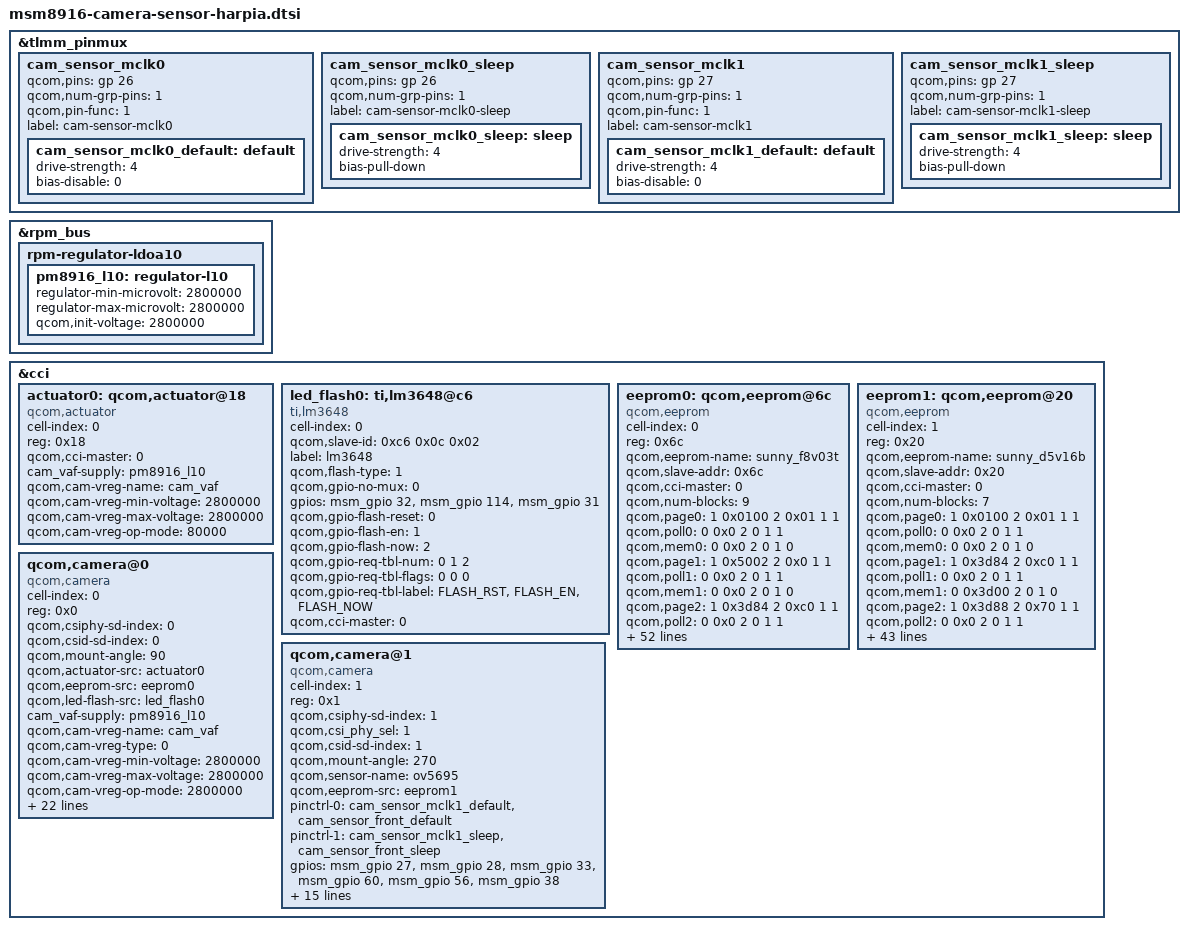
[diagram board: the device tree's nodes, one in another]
/*
 * Copyright (c) 2016, The Linux Foundation. All rights reserved.
 *
 * This program is free software; you can redistribute it and/or modify
 * it under the terms of the GNU General Public License version 2 and
 * only version 2 as published by the Free Software Foundation.
 *
 * This program is distributed in the hope that it will be useful,
 * but WITHOUT ANY WARRANTY; without even the implied warranty of
 * MERCHANTABILITY or FITNESS FOR A PARTICULAR PURPOSE.  See the
 * GNU General Public License for more details.
 */

&tlmm_pinmux {
	cam_sensor_mclk0 {
		/* MCLK */
		qcom,pins = <&gp 26>;
		qcom,num-grp-pins = <1>;
		qcom,pin-func = <1>;
		label = "cam-sensor-mclk0";
		/* active state */
		cam_sensor_mclk0_default: default {
			drive-strength = <4>; /* 4 MA */
			bias-disable = <0>; /* No PULL */
		};
	};

	cam_sensor_mclk0_sleep {
		/* MCLK */
		qcom,pins = <&gp 26>;
		qcom,num-grp-pins = <1>;
		label = "cam-sensor-mclk0-sleep";
		/* suspend state */
		cam_sensor_mclk0_sleep: sleep {
			drive-strength = <4>; /* 4 MA */
			bias-pull-down; /* PULL DOWN */
		};
	};

	cam_sensor_mclk1 {
		/* MCLK */
		qcom,pins = <&gp 27>;
		qcom,num-grp-pins = <1>;
		qcom,pin-func = <1>;
		label = "cam-sensor-mclk1";
		/* active state */
		cam_sensor_mclk1_default: default {
			drive-strength = <4>; /* 4 MA */
			bias-disable = <0>; /* No PULL */
		};
	};

	cam_sensor_mclk1_sleep {
		/* MCLK */
		qcom,pins = <&gp 27>;
		qcom,num-grp-pins = <1>;
		label = "cam-sensor-mclk1-sleep";
		/* suspend state */
		cam_sensor_mclk1_sleep: sleep {
			drive-strength = <4>; /* 4 MA */
			bias-pull-down; /* PULL DOWN */
		};
	};
};

&rpm_bus {
	rpm-regulator-ldoa10 {
		status = "okay";
		pm8916_l10: regulator-l10 {
			status = "okay";
			regulator-min-microvolt = <2800000>;
			regulator-max-microvolt = <2800000>;
			qcom,init-voltage = <2800000>;
		};
	};
};

&cci {

	actuator0: qcom,actuator@18 {
		cell-index = <0>;
		reg = <0x18>;
		compatible = "qcom,actuator";
		qcom,cci-master = <0>;
		cam_vaf-supply = <&pm8916_l10>;
		qcom,cam-vreg-name = "cam_vaf";
		qcom,cam-vreg-min-voltage = <2800000>;
		qcom,cam-vreg-max-voltage = <2800000>;
		qcom,cam-vreg-op-mode = <80000>;
	};

	/* LM3648 flash LED driver*/
	led_flash0: ti,lm3648@c6 {
		cell-index = <0>;
		qcom,slave-id = <0xc6 0x0c 0x02>;
		compatible = "ti,lm3648";
		label = "lm3648";
		qcom,flash-type = <1>;
		qcom,gpio-no-mux = <0>;
		gpios = <&msm_gpio 32 0>, /*FLASH_RST(HW_EN)*/
			<&msm_gpio 114 0>, /*TORCH_EN*/
			<&msm_gpio 31 0>; /*FLASH_NOW*/
		qcom,gpio-flash-reset = <0>;
		qcom,gpio-flash-en = <1>;
		qcom,gpio-flash-now = <2>;
		qcom,gpio-req-tbl-num = <0 1 2>;
		qcom,gpio-req-tbl-flags = <0 0 0>;
		qcom,gpio-req-tbl-label = "FLASH_RST",
			"FLASH_EN",
			"FLASH_NOW";
		qcom,cci-master = <0>;
	};

	eeprom0: qcom,eeprom@6c{
		cell-index = <0>;
		reg = <0x6c>;
		qcom,eeprom-name = "sunny_f8v03t";
		compatible = "qcom,eeprom";
		qcom,slave-addr = <0x6c>;
		qcom,cci-master = <0>;
		qcom,num-blocks = <9>;

		qcom,page0 = <1 0x0100 2 0x01 1 1>;
		qcom,poll0 = <0 0x0 2 0 1 1>;
		qcom,mem0 = <0 0x0 2 0 1 0>;

		qcom,page1 = <1 0x5002 2 0x0 1 1>;
		qcom,poll1 = <0 0x0 2 0 1 1>;
		qcom,mem1 = <0 0x0 2 0 1 0>;

		qcom,page2 = <1 0x3d84 2 0xc0 1 1>;
		qcom,poll2 = <0 0x0 2 0 1 1>;
		qcom,mem2 = <0 0x3d00 2 0 1 0>;

		qcom,page3 = <1 0x3d88 2 0x70 1 1>;
		qcom,poll3 = <0 0x0 2 0 1 1>;
		qcom,mem3 = <0 0x3d00 2 0 1 0>;

		qcom,page4 = <1 0x3d89 2 0x10 1 1>;
		qcom,poll4 = <0 0x0 2 0 1 1>;
		qcom,mem4 = <0 0x3d00 2 0 1 0>;

		qcom,page5 = <1 0x3d8A 2 0x71 1 1>;
		qcom,poll5 = <0 0x0 2 0 1 1>;
		qcom,mem5 = <0 0x3d00 2 0 1 0>;

		qcom,page6 = <1 0x3d8B 2 0x15 1 1>;
		qcom,poll6 = <0 0x0 2 0 1 1>;
		qcom,mem6 = <0 0x3d00 2 0 1 0>;

		qcom,page7 = <1 0x3d81 2 0x01 1 10>;
		qcom,poll7 = <0 0x0 2 0 1 1>;
		qcom,mem7 = <278 0x7000 2 0 1 1>;

		qcom,page8 = <1 0x5002 2 0x08 1 1>;
		qcom,poll8 = <0 0x0 2 0 1 1>;
		qcom,mem8 = <0 0x0 2 0 1 0>;

		pinctrl-names = "cam_default", "cam_suspend";
		pinctrl-0 = <&cam_sensor_mclk0_default &cam_sensor_rear_default>;
		pinctrl-1 = <&cam_sensor_mclk0_sleep &cam_sensor_rear_sleep>;
		qcom,gpio-no-mux = <0>;
		gpios = <&msm_gpio 26 0>,
			<&msm_gpio 35 0>,
			<&msm_gpio 34 0>,
			<&msm_gpio 60 0>,
			<&msm_gpio 56 0>,
			<&msm_gpio 38 0>;
		qcom,gpio-reset = <1>;
		qcom,gpio-standby = <2>;
		qcom,gpio-vio = <3>;
		qcom,gpio-vdig = <4>;
		qcom,gpio-vana= <5>;
		qcom,gpio-req-tbl-num = <0 1 2 3 4 5>;
		qcom,gpio-req-tbl-flags = <1 0 0 0 0 0>;
		qcom,gpio-req-tbl-label = "CAMIF_MCLK",
			"CAM_RESET1",
			"CAM_STANDBY",
			"CAM_VIO",
			"CAM_VDIG",
			"CAM_VANA";
		qcom,gpio-set-tbl-num = <1 1>;
		qcom,gpio-set-tbl-flags = <0 2>;
		qcom,gpio-set-tbl-delay = <1000 4000>;
		qcom,csi-lane-assign = <0x4320>;
		qcom,csi-lane-mask = <0x3>;
		qcom,cam-power-seq-type = "sensor_gpio", "sensor_gpio", "sensor_gpio",
			"sensor_gpio", "sensor_gpio" , "sensor_clk";
		qcom,cam-power-seq-val = "sensor_gpio_vana", "sensor_gpio_vio", "sensor_gpio_vdig",
			"sensor_gpio_reset", "sensor_gpio_standby","sensor_cam_mclk";
		qcom,cam-power-seq-cfg-val = <1 1 1 1 1 23880000>;
		qcom,cam-power-seq-delay = <1 2 1 10 10 10>;
		clocks = <&clock_gcc clk_mclk0_clk_src>,
				<&clock_gcc clk_gcc_camss_mclk0_clk>;
		clock-names = "cam_src_clk", "cam_clk";
	};

	eeprom1: qcom,eeprom@20 {
		cell-index = <1>;
		reg = <0x20>;
		qcom,eeprom-name = "sunny_d5v16b";
		compatible = "qcom,eeprom";
		qcom,slave-addr = <0x20>;
		qcom,cci-master = <0>;
		qcom,num-blocks = <7>;

		qcom,page0 = <1 0x0100 2 0x01 1 1>;
		qcom,poll0 = <0 0x0 2 0 1 1>;
		qcom,mem0 = <0 0x0 2 0 1 0>;

		qcom,page1 = <1 0x3d84 2 0xc0 1 1>;
		qcom,poll1 = <0 0x0 2 0 1 1>;
		qcom,mem1 = <0 0x3d00 2 0 1 0>;

		qcom,page2 = <1 0x3d88 2 0x70 1 1>;
		qcom,poll2 = <0 0x0 2 0 1 1>;
		qcom,mem2 = <0 0x3d00 2 0 1 0>;

		qcom,page3 = <1 0x3d89 2 0x0C 1 1>;
		qcom,poll3 = <0 0x0 2 0 1 1>;
		qcom,mem3 = <0 0x3d00 2 0 1 0>;

		qcom,page4 = <1 0x3d8A 2 0x70 1 1>;
		qcom,poll4 = <0 0x0 2 0 1 1>;
		qcom,mem4 = <0 0x3d00 2 0 1 0>;

		qcom,page5 = <1 0x3d8B 2 0x1B 1 1>;
		qcom,poll5 = <0 0x0 2 0 1 1>;
		qcom,mem5 = <0 0x3d00 2 0 1 0>;

		qcom,page6 = <1 0x3d81 2 0x01 1 10>;
		qcom,poll6 = <0 0x0 2 0 1 1>;
		qcom,mem6 = <28 0x7000 2 0 1 1>;

		pinctrl-names = "cam_default", "cam_suspend";
		pinctrl-0 = <&cam_sensor_mclk1_default &cam_sensor_front_default>;
		pinctrl-1 = <&cam_sensor_mclk1_sleep &cam_sensor_front_sleep>;
		gpios = <&msm_gpio 27 0>,
			<&msm_gpio 28 0>,
			<&msm_gpio 33 0>,
			<&msm_gpio 60 0>,
			<&msm_gpio 56 0>,
			<&msm_gpio 38 0>;
		qcom,gpio-reset = <1>;
		qcom,gpio-standby = <2>;
		qcom,gpio-vio = <3>;
		qcom,gpio-vdig = <4>;
		qcom,gpio-vana = <5>;
		qcom,gpio-req-tbl-num = <0 1 2 3 4 5>;
		qcom,gpio-req-tbl-flags = <1 0 0 0 0 0>;
		qcom,gpio-req-tbl-label = "CAMIF_MCLK",
			"CAM_RESET",
			"CAM_STANDBY",
			"CAM_VIO",
			"CAM_VDIG",
			"CAM_VANA";
		qcom,gpio-set-tbl-num = <1 1>;
		qcom,gpio-set-tbl-flags = <0 2>;
		qcom,gpio-set-tbl-delay = <1000 4000>;
		qcom,cam-power-seq-type = "sensor_gpio", "sensor_gpio", "sensor_gpio",
			"sensor_gpio", "sensor_gpio" , "sensor_clk";
		qcom,cam-power-seq-val = "sensor_gpio_vana", "sensor_gpio_vio", "sensor_gpio_vdig",
			"sensor_gpio_standby", "sensor_gpio_reset", "sensor_cam_mclk";
		qcom,cam-power-seq-cfg-val = <1 1 1 1 1 23880000>;
		qcom,cam-power-seq-delay = <1 2 1 10 10 10>;
		clocks = <&clock_gcc clk_mclk1_clk_src>,
				<&clock_gcc clk_gcc_camss_mclk1_clk>;
		clock-names = "cam_src_clk", "cam_clk";
	};

	qcom,camera@0 {
		cell-index = <0>;
		compatible = "qcom,camera";
		reg = <0x0>;
		qcom,csiphy-sd-index = <0>;
		qcom,csid-sd-index = <0>;
		qcom,mount-angle = <90>;
		qcom,actuator-src = <&actuator0>;
		qcom,eeprom-src = <&eeprom0>;
		qcom,led-flash-src = <&led_flash0>;
		cam_vaf-supply = <&pm8916_l10>;
		qcom,cam-vreg-name = "cam_vaf";
		qcom,cam-vreg-type = <0>;
		qcom,cam-vreg-min-voltage = <2800000>;
		qcom,cam-vreg-max-voltage = <2800000>;
		qcom,cam-vreg-op-mode = <2800000>;
		pinctrl-names = "cam_default", "cam_suspend";
		pinctrl-0 = <&cam_sensor_mclk0_default &cam_sensor_rear_default>;
		pinctrl-1 = <&cam_sensor_mclk0_sleep &cam_sensor_rear_sleep>;
		gpios = <&msm_gpio 26 0>,
			<&msm_gpio 35 0>,
			<&msm_gpio 34 0>,
			<&msm_gpio 60 0>,
			<&msm_gpio 56 0>,
			<&msm_gpio 38 0>;
		qcom,gpio-reset = <1>;
		qcom,gpio-standby = <2>;
		qcom,gpio-vio = <3>;
		qcom,gpio-vdig = <4>;
		qcom,gpio-vana= <5>;
		qcom,gpio-req-tbl-num = <0 1 2 3 4 5>;
		qcom,gpio-req-tbl-flags = <1 0 0 0 0 0>;
		qcom,gpio-req-tbl-label = "CAMIF_MCLK",
			"CAM_RESET1",
			"CAM_STANDBY",
			"CAM_VIO",
			"CAM_VDIG",
			"CAM_VANA";
		qcom,sensor-position = <0>;
		qcom,sensor-mode = <0>;
		qcom,cci-master = <0>;
		qcom,mclk-23880000;
		status = "ok";
		clocks = <&clock_gcc clk_mclk0_clk_src>,
				<&clock_gcc clk_gcc_camss_mclk0_clk>;
		clock-names = "cam_src_clk", "cam_clk";
	};

	qcom,camera@1 {
		cell-index = <1>;
		compatible = "qcom,camera";
		reg = <0x1>;
		qcom,csiphy-sd-index = <1>;
		qcom,csi_phy_sel = <1>;
		qcom,csid-sd-index = <1>;
		qcom,mount-angle = <270>;
		qcom,sensor-name = "ov5695";
		qcom,eeprom-src = <&eeprom1>;
		pinctrl-names = "cam_default", "cam_suspend";
		pinctrl-0 = <&cam_sensor_mclk1_default &cam_sensor_front_default>;
		pinctrl-1 = <&cam_sensor_mclk1_sleep &cam_sensor_front_sleep>;
		gpios = <&msm_gpio 27 0>,
			<&msm_gpio 28 0>,
			<&msm_gpio 33 0>,
			<&msm_gpio 60 0>,
			<&msm_gpio 56 0>,
			<&msm_gpio 38 0>;
		qcom,gpio-reset = <1>;
		qcom,gpio-standby = <2>;
		qcom,gpio-vio = <3>;
		qcom,gpio-vdig = <4>;
		qcom,gpio-vana = <5>;
		qcom,gpio-req-tbl-num = <0 1 2 3 4 5>;
		qcom,gpio-req-tbl-flags = <1 0 0 0 0 0>;
		qcom,gpio-req-tbl-label = "CAMIF_MCLK",
			"CAM_RESET",
			"CAM_STANDBY",
			"CAM_VIO",
			"CAM_VDIG",
			"CAM_VANA";
		qcom,sensor-mode = <1>;
		qcom,cci-master = <0>;
		qcom,mclk-23880000;
		status = "ok";
		clocks = <&clock_gcc clk_mclk1_clk_src>,
				<&clock_gcc clk_gcc_camss_mclk1_clk>;
		clock-names = "cam_src_clk", "cam_clk";
	};
};
